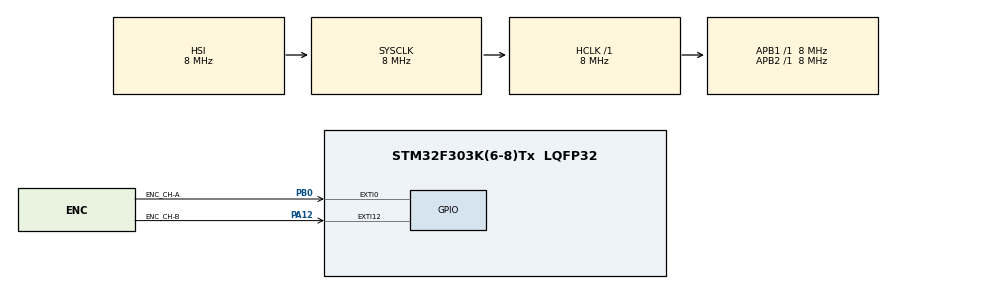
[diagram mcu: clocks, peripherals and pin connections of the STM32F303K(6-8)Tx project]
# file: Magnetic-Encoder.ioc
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Mcu.Family=STM32F3
Mcu.Name=STM32F303K(6-8)Tx
Mcu.Package=LQFP32
NVIC.EXTI0_IRQn=true\:0\:0\:false\:false\:true\:true\:true
NVIC.EXTI15_10_IRQn=true\:0\:0\:false\:false\:true\:true\:true
NVIC.PriorityGroup=NVIC_PRIORITYGROUP_4
NVIC.TIM2_IRQn=true\:0\:0\:false\:false\:true\:true\:true
PA12.GPIO_Label=ENC_CH-B
PA12.Signal=GPXTI12
PB0.GPIO_Label=ENC_CH-A
PB0.Signal=GPXTI0
ProjectManager.HeapSize=0x200
ProjectManager.StackSize=0x400
ProjectManager.TargetToolchain=TrueSTUDIO
RCC.AHBFreq_Value=8000000
RCC.APB1Freq_Value=8000000
RCC.APB2Freq_Value=8000000
RCC.CortexFreq_Value=8000000
RCC.HSE_VALUE=8000000
RCC.HSI_VALUE=8000000
RCC.SYSCLKFreq_VALUE=8000000
TIM2.Period=10
TIM2.Prescaler=8
VP_TIM2_VS_ClockSourceINT.Mode=Internal
VP_TIM2_VS_OPM.Mode=OPM_bit
board=custom

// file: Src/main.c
/* USER CODE BEGIN Header */
/**
  ******************************************************************************
  * @file           : main.c
  * @brief          : Main program body
  ******************************************************************************
  * @attention
  *
  * <h2><center>&copy; Copyright (c) 2019 STMicroelectronics.
  * All rights reserved.</center></h2>
  *
  * This software component is licensed by ST under BSD 3-Clause license,
  * the "License"; You may not use this file except in compliance with the
  * License. You may obtain a copy of the License at:
  *                        opensource.org/licenses/BSD-3-Clause
  *
  ******************************************************************************
  */
/* USER CODE END Header */

#include "main.h"

TIM_HandleTypeDef htim2;

void SystemClock_Config(void);
static void MX_GPIO_Init(void);
static void MX_TIM2_Init(void);

/* USER CODE BEGIN 0 */
uint8_t lock_encoder = 0;

int cont_foward = 0;
int cont_backrd = 0;
/* USER CODE END 0 */

int main(void)
{

  /* MCU Configuration--------------------------------------------------------*/

  /* Reset of all peripherals, Initializes the Flash interface and the Systick. */
  HAL_Init();

  /* Configure the system clock */
  SystemClock_Config();

  /* Initialize all configured peripherals */
  MX_GPIO_Init();
  MX_TIM2_Init();

  /* Infinite loop */
  while (1)
  {

  }
}

void SystemClock_Config(void)
{
  RCC_OscInitTypeDef RCC_OscInitStruct = {0};
  RCC_ClkInitTypeDef RCC_ClkInitStruct = {0};

  /** Initializes the CPU, AHB and APB busses clocks
  */
  RCC_OscInitStruct.OscillatorType = RCC_OSCILLATORTYPE_HSI;
  RCC_OscInitStruct.HSIState = RCC_HSI_ON;
  RCC_OscInitStruct.HSICalibrationValue = RCC_HSICALIBRATION_DEFAULT;
  RCC_OscInitStruct.PLL.PLLState = RCC_PLL_NONE;
  if (HAL_RCC_OscConfig(&RCC_OscInitStruct) != HAL_OK)
  {
    Error_Handler();
  }
  /** Initializes the CPU, AHB and APB busses clocks
  */
  RCC_ClkInitStruct.ClockType = RCC_CLOCKTYPE_HCLK|RCC_CLOCKTYPE_SYSCLK
                              |RCC_CLOCKTYPE_PCLK1|RCC_CLOCKTYPE_PCLK2;
  RCC_ClkInitStruct.SYSCLKSource = RCC_SYSCLKSOURCE_HSI;
  RCC_ClkInitStruct.AHBCLKDivider = RCC_SYSCLK_DIV1;
  RCC_ClkInitStruct.APB1CLKDivider = RCC_HCLK_DIV1;
  RCC_ClkInitStruct.APB2CLKDivider = RCC_HCLK_DIV1;

  if (HAL_RCC_ClockConfig(&RCC_ClkInitStruct, FLASH_LATENCY_0) != HAL_OK)
  {
    Error_Handler();
  }
}

static void MX_TIM2_Init(void)
{

  TIM_ClockConfigTypeDef sClockSourceConfig = {0};
  TIM_MasterConfigTypeDef sMasterConfig = {0};

  htim2.Instance = TIM2;
  htim2.Init.Prescaler = 8;
  htim2.Init.CounterMode = TIM_COUNTERMODE_UP;
  htim2.Init.Period = 10;
  htim2.Init.ClockDivision = TIM_CLOCKDIVISION_DIV1;
  htim2.Init.AutoReloadPreload = TIM_AUTORELOAD_PRELOAD_DISABLE;
  if (HAL_TIM_Base_Init(&htim2) != HAL_OK)
  {
    Error_Handler();
  }
  sClockSourceConfig.ClockSource = TIM_CLOCKSOURCE_INTERNAL;
  if (HAL_TIM_ConfigClockSource(&htim2, &sClockSourceConfig) != HAL_OK)
  {
    Error_Handler();
  }
  if (HAL_TIM_OnePulse_Init(&htim2, TIM_OPMODE_SINGLE) != HAL_OK)
  {
    Error_Handler();
  }
  sMasterConfig.MasterOutputTrigger = TIM_TRGO_RESET;
  sMasterConfig.MasterSlaveMode = TIM_MASTERSLAVEMODE_DISABLE;
  if (HAL_TIMEx_MasterConfigSynchronization(&htim2, &sMasterConfig) != HAL_OK)
  {
    Error_Handler();
  }

}

static void MX_GPIO_Init(void)
{
  GPIO_InitTypeDef GPIO_InitStruct = {0};

  /* GPIO Ports Clock Enable */
  __HAL_RCC_GPIOB_CLK_ENABLE();
  __HAL_RCC_GPIOA_CLK_ENABLE();

  /*Configure GPIO pin : ENC_CH_A_Pin */
  GPIO_InitStruct.Pin = ENC_CH_A_Pin;
  GPIO_InitStruct.Mode = GPIO_MODE_IT_RISING;
  GPIO_InitStruct.Pull = GPIO_NOPULL;
  HAL_GPIO_Init(ENC_CH_A_GPIO_Port, &GPIO_InitStruct);

  /*Configure GPIO pin : ENC_CH_B_Pin */
  GPIO_InitStruct.Pin = ENC_CH_B_Pin;
  GPIO_InitStruct.Mode = GPIO_MODE_IT_RISING;
  GPIO_InitStruct.Pull = GPIO_NOPULL;
  HAL_GPIO_Init(ENC_CH_B_GPIO_Port, &GPIO_InitStruct);

  /* EXTI interrupt init*/
  HAL_NVIC_SetPriority(EXTI0_IRQn, 0, 0);
  HAL_NVIC_EnableIRQ(EXTI0_IRQn);

  HAL_NVIC_SetPriority(EXTI15_10_IRQn, 0, 0);
  HAL_NVIC_EnableIRQ(EXTI15_10_IRQn);

}

/* USER CODE BEGIN 4 */

// RTI interrupção da GPIO
void HAL_GPIO_EXTI_Callback(uint16_t GPIO_Pin)
{
	// se a interrupção ocorreu pela borda de subida do canal-A
	// ock_encoder é para travar a execução da RTI e esperar pelo debouoncer
	if(GPIO_Pin==ENC_CH_A_Pin && !lock_encoder)
	{
		// se o canal-B estiver em nível alto
		if(HAL_GPIO_ReadPin(GPIOA, ENC_CH_B_Pin)==GPIO_PIN_SET)
			cont_foward += 1;
		else
			cont_backrd += 1;

		lock_encoder=1;// travar a RTI
		__HAL_TIM_CLEAR_IT(&htim2, TIM_IT_UPDATE);// zerar o timer 2
		HAL_TIM_Base_Start_IT(&htim2);// inciar o timer 2 para debounceer
	}
	if(GPIO_Pin==ENC_CH_B_Pin && !lock_encoder)
	{
		// se o canal-A estiver em nível baixo
		if(HAL_GPIO_ReadPin(GPIOB, ENC_CH_A_Pin)==GPIO_PIN_RESET)
			cont_foward += 1;
		else
			cont_backrd += 1;

		lock_encoder=1;// travar a RTI
		__HAL_TIM_CLEAR_IT(&htim2, TIM_IT_UPDATE);// zerar o timer 2
		HAL_TIM_Base_Start_IT(&htim2);// inciar o timer 2 para debounceer
	}
}

void HAL_TIM_PeriodElapsedCallback(TIM_HandleTypeDef *htim)
{
	// saber qual timer acionou a interrupção
	if(htim->Instance == TIM2)
	{
		HAL_TIM_Base_Stop_IT(&htim2);// parar o timer 2
		lock_encoder=0;// habilitar o encoder novamente

		// habilitar a requisição de interrupção
		HAL_NVIC_EnableIRQ(EXTI0_IRQn);
		HAL_NVIC_EnableIRQ(EXTI15_10_IRQn);
	}
	else
		__NOP();
}
/* USER CODE END 4 */

void Error_Handler(void)
{
}

/************************ (C) COPYRIGHT STMicroelectronics *****END OF FILE****/
